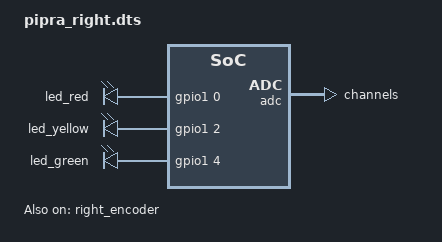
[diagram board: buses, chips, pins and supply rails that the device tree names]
/*
 * Copyright (c) 2025 The ZMK Contributors
 *
 * SPDX-License-Identifier: MIT
 */

#include "pipra.dtsi"

&default_transform {
    col-offset = <6>;
};

&adc {
    channel@1 {
        zephyr,input-positive = <NRF_SAADC_AIN3>; // P0.05
    };
};

&amux {
    select-gpios
        = <&gpio0 29 GPIO_ACTIVE_HIGH>
        , <&gpio0  2 GPIO_ACTIVE_HIGH>
        , <&gpio1 13 GPIO_ACTIVE_HIGH>
        ;
    en-gpios = <&gpio0 31 GPIO_ACTIVE_LOW>;
};

&right_encoder {
    status = "okay";
};

&led_red {
    gpios = <&gpio1 0 (GPIO_ACTIVE_HIGH | NRF_GPIO_DRIVE_H0H1)>;
};

&led_yellow {
    gpios = <&gpio1 2 (GPIO_ACTIVE_HIGH | NRF_GPIO_DRIVE_H0H1)>;
};

&led_green {
    gpios = <&gpio1 4 (GPIO_ACTIVE_HIGH | NRF_GPIO_DRIVE_H0H1)>;
};

&kscan0 {
    input-gpios
        = <&amux 2 0>
        , <&amux 5 0>
        , <&amux 7 0>
        , <&amux 6 0>
        , <&amux 4 0>
        , <&amux 3 0>
        ;
    io-channels = <&adc 1>;
    strobe-gpios
        = <&gpio0 4 GPIO_ACTIVE_HIGH>
        , <&gpio0 8 GPIO_ACTIVE_HIGH>
        , <&gpio0 6 GPIO_ACTIVE_HIGH>
        ;
    strobe-input-masks = <
        BIT(5)
        0
        (BIT(0) + BIT(4))
    >;
    drain-gpios = <&gpio0 30 (GPIO_ACTIVE_HIGH | NRF_GPIO_DRIVE_H0H1)>;
    power-gpios = <&gpio0 12 GPIO_ACTIVE_HIGH>;
};

&pinctrl {
    i2c0_default: i2c0_default {
        group1 {
            psels = <NRF_PSEL(TWIM_SDA, 0, 13)>,
                    <NRF_PSEL(TWIM_SCL, 0, 24)>;
        };
    };

    i2c0_sleep: i2c0_sleep {
        group1 {
            psels = <NRF_PSEL(TWIM_SDA, 0, 13)>,
                    <NRF_PSEL(TWIM_SCL, 0, 24)>;
            low-power-enable;
        };
    };
};
